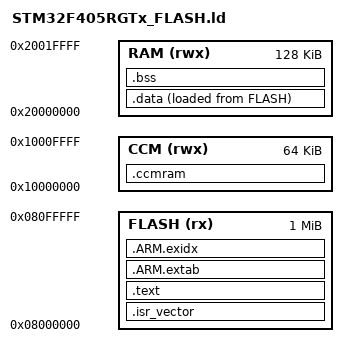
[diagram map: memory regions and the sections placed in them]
ENTRY(Reset_Handler)

MEMORY
{
    FLASH (rx)  : ORIGIN = 0x08000000, LENGTH = 1024K
    RAM   (rwx) : ORIGIN = 0x20000000, LENGTH = 128K
    CCM   (rwx) : ORIGIN = 0x10000000, LENGTH = 64K
}

_estack = ORIGIN(RAM) + LENGTH(RAM);

SECTIONS
{
    .isr_vector :
    {
        . = ALIGN(4);
        KEEP(*(.isr_vector))
        . = ALIGN(4);
    } > FLASH

    .text :
    {
        . = ALIGN(4);
        *(.text)
        *(.text*)
        *(.rodata)
        *(.rodata*)
        . = ALIGN(4);
        _etext = .;
    } > FLASH

    .ARM.extab :
    {
        *(.ARM.extab* .gnu.linkonce.armextab.*)
    } > FLASH

    .ARM.exidx :
    {
        __exidx_start = .;
        *(.ARM.exidx* .gnu.linkonce.armexidx.*)
        __exidx_end = .;
    } > FLASH

    _sidata = LOADADDR(.data);

    .data :
    {
        . = ALIGN(4);
        _sdata = .;
        *(.data)
        *(.data*)
        . = ALIGN(4);
        _edata = .;
    } > RAM AT > FLASH

    .bss (NOLOAD) :
    {
        . = ALIGN(4);
        _sbss = .;
        *(.bss)
        *(.bss*)
        *(COMMON)
        . = ALIGN(4);
        _ebss = .;
    } > RAM

    .ccmram (NOLOAD) :
    {
        . = ALIGN(4);
        *(.ccmram)
        *(.ccmram*)
        . = ALIGN(4);
    } > CCM

    /DISCARD/ :
    {
        libc.a(*)
        libm.a(*)
    }
}
